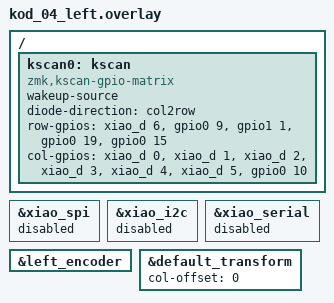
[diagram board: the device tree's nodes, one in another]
/*
 * Copyright (c) 2024 kodomari
 * SPDX-License-Identifier: MIT
 */
#include "kod_04.dtsi"

&xiao_spi { status = "disabled"; };
&xiao_i2c { status = "disabled"; };
&xiao_serial { status = "disabled"; };

/ {
    kscan0: kscan {
        compatible = "zmk,kscan-gpio-matrix";
        wakeup-source;
        diode-direction = "col2row";

        row-gpios
          = <&xiao_d 6  (GPIO_ACTIVE_HIGH | GPIO_PULL_DOWN)>
          , <&gpio0 9   (GPIO_ACTIVE_HIGH | GPIO_PULL_DOWN)>
          , <&gpio1 1   (GPIO_ACTIVE_HIGH | GPIO_PULL_DOWN)>
          , <&gpio0 19  (GPIO_ACTIVE_HIGH | GPIO_PULL_DOWN)>
          , <&gpio0 15  (GPIO_ACTIVE_HIGH | GPIO_PULL_DOWN)>
          ;

        col-gpios
          = <&xiao_d 0  GPIO_ACTIVE_HIGH>
          , <&xiao_d 1  GPIO_ACTIVE_HIGH>
          , <&xiao_d 2  GPIO_ACTIVE_HIGH>
          , <&xiao_d 3  GPIO_ACTIVE_HIGH>
          , <&xiao_d 4  GPIO_ACTIVE_HIGH>
          , <&xiao_d 5  GPIO_ACTIVE_HIGH>
          , <&gpio0 10  GPIO_ACTIVE_HIGH>
          ;
    };
};

&left_encoder {
    status = "okay";
};

&default_transform {
    col-offset = <0>;
};
